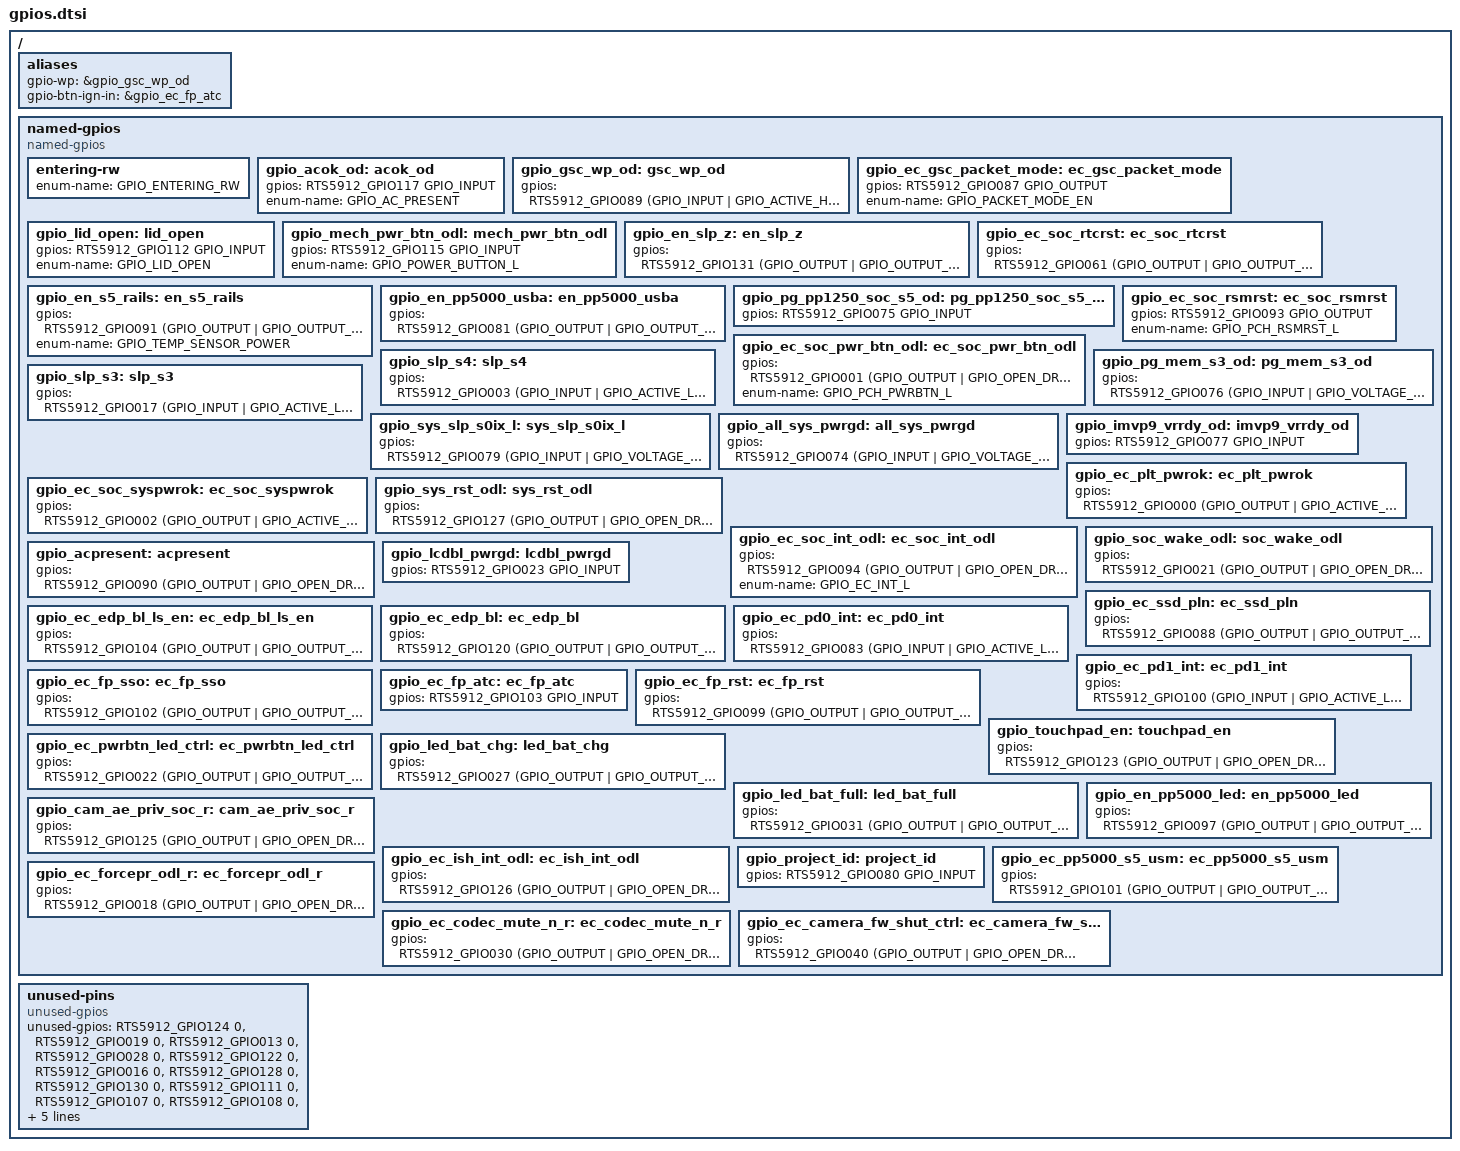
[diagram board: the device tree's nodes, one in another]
/* Copyright 2026 The ChromiumOS Authors
 * Use of this source code is governed by a BSD-style license that can be
 * found in the LICENSE file.
 */

/ {
	aliases {
		gpio-wp = &gpio_gsc_wp_od;
		gpio-btn-ign-in = &gpio_ec_fp_atc;
	};

	named-gpios {
		compatible = "named-gpios";

		/* unimplemented GPIOs */
		entering-rw {
			enum-name = "GPIO_ENTERING_RW";
		};

		/* EC_A4 ACOK_OD */
		gpio_acok_od: acok_od {
			gpios = <RTS5912_GPIO117 GPIO_INPUT>;
			enum-name = "GPIO_AC_PRESENT";
		};
		/* EC_A10 GSC_WP_OD */
		gpio_gsc_wp_od: gsc_wp_od {
			gpios = <RTS5912_GPIO089 (GPIO_INPUT | GPIO_ACTIVE_HIGH)>;
		};
		/* EC_B13 EC_GSC_PACKET_MODE */
		gpio_ec_gsc_packet_mode: ec_gsc_packet_mode {
			gpios = <RTS5912_GPIO087 GPIO_OUTPUT>;
			enum-name = "GPIO_PACKET_MODE_EN";
		};
		/* LID_OPEN */
		gpio_lid_open: lid_open {
			gpios = <RTS5912_GPIO112 GPIO_INPUT>;
			enum-name = "GPIO_LID_OPEN";
		};
		/* EC_B4 MECH_PWR_BTN */
		gpio_mech_pwr_btn_odl: mech_pwr_btn_odl {
			gpios = <RTS5912_GPIO115 GPIO_INPUT>;
			enum-name = "GPIO_POWER_BUTTON_L";
		};

		/* EC_EN_Z1_RAILS */
		gpio_en_slp_z: en_slp_z {
			gpios = <RTS5912_GPIO131 (GPIO_OUTPUT | GPIO_OUTPUT_INIT_HIGH)>;
		};
		/* EC_RTC_RST */
		gpio_ec_soc_rtcrst: ec_soc_rtcrst {
			gpios = <RTS5912_GPIO061 (GPIO_OUTPUT | GPIO_OUTPUT_INIT_LOW)>;
		};
		/* EN_S5_RAILS */
		gpio_en_s5_rails: en_s5_rails {
			gpios = <RTS5912_GPIO091 (GPIO_OUTPUT | GPIO_OUTPUT_INIT_LOW)>;
			enum-name = "GPIO_TEMP_SENSOR_POWER";
		};
		/* EN_PP5000_USBA */
		gpio_en_pp5000_usba: en_pp5000_usba {
			gpios = <RTS5912_GPIO081 (GPIO_OUTPUT | GPIO_OUTPUT_INIT_LOW)>;
		};
		/* PG_PP1250_SOC_S5_OD */
		gpio_pg_pp1250_soc_s5_od: pg_pp1250_soc_s5_od {
			gpios = <RTS5912_GPIO075 GPIO_INPUT>;
		};
		/* EC_SOC_RSMRST */
		gpio_ec_soc_rsmrst: ec_soc_rsmrst {
			gpios = <RTS5912_GPIO093 GPIO_OUTPUT>;
			enum-name = "GPIO_PCH_RSMRST_L";
		};
		/* EC_SOC_PWR_BTN_ODL */
		gpio_ec_soc_pwr_btn_odl: ec_soc_pwr_btn_odl {
			gpios = <RTS5912_GPIO001 (GPIO_OUTPUT | GPIO_OPEN_DRAIN | GPIO_ACTIVE_LOW)>;
			enum-name = "GPIO_PCH_PWRBTN_L";
		};
		/* SLP_S4_L */
		gpio_slp_s4: slp_s4 {
			gpios = <RTS5912_GPIO003 (GPIO_INPUT | GPIO_ACTIVE_LOW | GPIO_VOLTAGE_1P8)>;
		};
		/* PG_MEM_S3_OD */
		gpio_pg_mem_s3_od: pg_mem_s3_od {
			gpios = <RTS5912_GPIO076 (GPIO_INPUT | GPIO_VOLTAGE_1P8)>;
		};
		/* SLP_S3_L */
		gpio_slp_s3: slp_s3 {
			gpios = <RTS5912_GPIO017 (GPIO_INPUT | GPIO_ACTIVE_LOW | GPIO_VOLTAGE_1P8)>;
		};
		/* EC_F10 SYS_SLP_S0IX_L */
		gpio_sys_slp_s0ix_l: sys_slp_s0ix_l {
			gpios = <RTS5912_GPIO079 (GPIO_INPUT | GPIO_VOLTAGE_1P8)>;
		};
		/* ALL_SYS_PWRGD */
		gpio_all_sys_pwrgd: all_sys_pwrgd {
			gpios = <RTS5912_GPIO074 (GPIO_INPUT | GPIO_VOLTAGE_1P8)>;
		};
		/* IMVP9_VRRDY_OD */
		gpio_imvp9_vrrdy_od: imvp9_vrrdy_od {
			gpios = <RTS5912_GPIO077 GPIO_INPUT>;
		};
		/* EC_PLT_PWROK */
		gpio_ec_plt_pwrok: ec_plt_pwrok {
			gpios = <RTS5912_GPIO000 (GPIO_OUTPUT | GPIO_ACTIVE_HIGH | GPIO_OUTPUT_INIT_LOW)>;
		};
		/* EC_SOC_SYS_PWROK */
		gpio_ec_soc_syspwrok: ec_soc_syspwrok {
			gpios = <RTS5912_GPIO002 (GPIO_OUTPUT | GPIO_ACTIVE_HIGH | GPIO_OUTPUT_INIT_LOW)>;
		};

		/* SYS_RST_ODL */
		gpio_sys_rst_odl: sys_rst_odl {
			gpios = <RTS5912_GPIO127 (GPIO_OUTPUT | GPIO_OPEN_DRAIN | GPIO_ACTIVE_LOW | GPIO_OUTPUT_INIT_HIGH)>;
		};
		/* EC_A13 */
		gpio_ec_soc_int_odl: ec_soc_int_odl {
			gpios = <RTS5912_GPIO094 (GPIO_OUTPUT | GPIO_OPEN_DRAIN | GPIO_ACTIVE_LOW | GPIO_OUTPUT_INIT_HIGH)>;
			enum-name = "GPIO_EC_INT_L";
		};
		/* EC_N4 SOC_WAKE_ODL
		 * Not to be marked as active low, the lpc_update_wake() already
		 * has the logic to invert the value.
		 */
		gpio_soc_wake_odl: soc_wake_odl {
			gpios = <RTS5912_GPIO021 (GPIO_OUTPUT | GPIO_OPEN_DRAIN | GPIO_OUTPUT_INIT_HIGH)>;
		};

		/* ACPRESENT */
		gpio_acpresent: acpresent{
			gpios = <RTS5912_GPIO090 (GPIO_OUTPUT | GPIO_OPEN_DRAIN | GPIO_OUTPUT_INIT_HIGH | GPIO_VOLTAGE_1P8)>;
		};
		/* EC_SSD_PLN */
		gpio_ec_ssd_pln: ec_ssd_pln {
			gpios = <RTS5912_GPIO088 (GPIO_OUTPUT | GPIO_OUTPUT_INIT_LOW)>;
		};
		/* EC_A8 EC_EDP_BL_LS_EN */
		gpio_ec_edp_bl_ls_en: ec_edp_bl_ls_en {
			gpios = <RTS5912_GPIO104 (GPIO_OUTPUT | GPIO_OUTPUT_INIT_LOW)>;
		};
		/* LCDBL_PWRGD */
		gpio_lcdbl_pwrgd: lcdbl_pwrgd {
			gpios = <RTS5912_GPIO023 GPIO_INPUT>;
		};
		/* EC_B1 EC_EN_EDP_BL*/
		gpio_ec_edp_bl: ec_edp_bl {
			gpios = <RTS5912_GPIO120 (GPIO_OUTPUT | GPIO_OUTPUT_INIT_LOW)>;
		};
		/* EC_PD0_INT */
		gpio_ec_pd0_int: ec_pd0_int {
			gpios = <RTS5912_GPIO083 (GPIO_INPUT | GPIO_ACTIVE_LOW)>;
		};
		/* EC_PD1_INT */
		gpio_ec_pd1_int: ec_pd1_int {
			gpios = <RTS5912_GPIO100 (GPIO_INPUT | GPIO_ACTIVE_LOW)>;
		};
		/* EC_FP_SSO */
		gpio_ec_fp_sso: ec_fp_sso {
			gpios = <RTS5912_GPIO102 (GPIO_OUTPUT | GPIO_OUTPUT_INIT_LOW)>;
		};
		/* EC_FP_ATC */
		gpio_ec_fp_atc: ec_fp_atc {
			gpios = <RTS5912_GPIO103 GPIO_INPUT>;
		};
		/* EC_FPR_RST */
		gpio_ec_fp_rst: ec_fp_rst {
			gpios = <RTS5912_GPIO099 (GPIO_OUTPUT | GPIO_OUTPUT_INIT_HIGH)>;
		};
		/* TOUCHPAD_EN */
		gpio_touchpad_en: touchpad_en {
			gpios = <RTS5912_GPIO123 (GPIO_OUTPUT | GPIO_OPEN_DRAIN | GPIO_OUTPUT_INIT_LOW)>;
		};
		/* EC_PWRBTN_LED_CTRL */
		gpio_ec_pwrbtn_led_ctrl: ec_pwrbtn_led_ctrl {
			gpios = <RTS5912_GPIO022 (GPIO_OUTPUT | GPIO_OUTPUT_INIT_LOW)>;
		};
		/* LED_BAT_CHG orange */
		gpio_led_bat_chg: led_bat_chg {
			gpios = <RTS5912_GPIO027 (GPIO_OUTPUT | GPIO_OUTPUT_INIT_LOW)>;
		};
		/* LED_BAT_FULL white */
		gpio_led_bat_full: led_bat_full {
			gpios = <RTS5912_GPIO031 (GPIO_OUTPUT | GPIO_OUTPUT_INIT_LOW)>;
		};
		/* EN_PP5000_LED_X lightbar */
		gpio_en_pp5000_led: en_pp5000_led {
			gpios = <RTS5912_GPIO097 (GPIO_OUTPUT | GPIO_OUTPUT_INIT_HIGH)>;
		};
		/* EC_D2 CAM_AE_PRIV_SOC_R */
		gpio_cam_ae_priv_soc_r: cam_ae_priv_soc_r {
			gpios = <RTS5912_GPIO125 (GPIO_OUTPUT | GPIO_OPEN_DRAIN | GPIO_OUTPUT_INIT_HIGH)>;
		};
		/* EC_E1 EC_ISH_INT_ODL */
		gpio_ec_ish_int_odl: ec_ish_int_odl {
			gpios = <RTS5912_GPIO126 (GPIO_OUTPUT | GPIO_OPEN_DRAIN | GPIO_OUTPUT_INIT_HIGH)>;
		};
		/* PROJECT_ID */
		gpio_project_id: project_id {
			gpios = <RTS5912_GPIO080 GPIO_INPUT>;
		};
		/* EC_PP5000_S5_USM */
		gpio_ec_pp5000_s5_usm: ec_pp5000_s5_usm {
			gpios = <RTS5912_GPIO101 (GPIO_OUTPUT | GPIO_OUTPUT_INIT_LOW)>;
		};
		/* EC_M3 EC_FORCEPR_ODL_R */
		gpio_ec_forcepr_odl_r: ec_forcepr_odl_r {
			gpios = <RTS5912_GPIO018 (GPIO_OUTPUT | GPIO_OPEN_DRAIN | GPIO_OUTPUT_INIT_HIGH)>;
		};
		/* EC_M3 CODEC_EC_MUTE_N_R */
		gpio_ec_codec_mute_n_r: ec_codec_mute_n_r {
			gpios = <RTS5912_GPIO030 (GPIO_OUTPUT | GPIO_OPEN_DRAIN | GPIO_OUTPUT_INIT_HIGH)>;
		};
		/* EC_CAMERA_FW_SHUT_CTRL */
		gpio_ec_camera_fw_shut_ctrl: ec_camera_fw_shut_ctrl {
			gpios = <RTS5912_GPIO040 (GPIO_OUTPUT | GPIO_OPEN_DRAIN | GPIO_OUTPUT_INIT_LOW)>;
		};
	};

	unused-pins {
		compatible = "unused-gpios";
		unused-gpios =
			<RTS5912_GPIO124 0>,	/* EC_KB_CAP_LED */
			<RTS5912_GPIO019 0>,	/* EC_SMB3_SDA_R */
			<RTS5912_GPIO013 0>,	/* EC_KB_LED_F4 */
			<RTS5912_GPIO028 0>,	/* EC_KB_F11_LED */
			<RTS5912_GPIO122 0>,	/* EC_SOC_EDP_BL_EN */
			<RTS5912_GPIO016 0>,	/* EC_SMB3_SCL_R */
			<RTS5912_GPIO128 0>,	/* EC_F1 */
			<RTS5912_GPIO130 0>,	/* SPI_FLASH2_HOLD_R */
			<RTS5912_GPIO111 0>,	/* EC_FLASH_SPI_CLK */
			<RTS5912_GPIO107 0>,	/* EC_FLASH_SPI_CS_N */
			<RTS5912_GPIO108 0>,	/* EC_STRAP0 EC_FLASH_SPI_MOSI_R */
			<RTS5912_GPIO109 0>,	/* EC_FLASH_SPI_MISO */
			<RTS5912_GPIO015 0>,	/* EC_LPBH */
			<RTS5912_GPIO086 0>, 	/* EC_C13 */
			<RTS5912_GPIO092 0>,	/* D_DOOR_SW */
			<RTS5912_GPIO106 0>,	/* EC_STRAP1 */
			<RTS5912_GPIO095 0>,	/* EC_A12 */
			<RTS5912_GPIO078 0>,	/* EC_CHG_MOD1_P1 */
			<RTS5912_GPIO060 0>,	/* EC_HDMI_HPD_L_STRAP */
			<RTS5912_GPIO105 0>,	/* EC_SOC_ME_UNLOCK_R */
			<RTS5912_GPIO084 0>;	/* EC_CATERR */
	};
};
